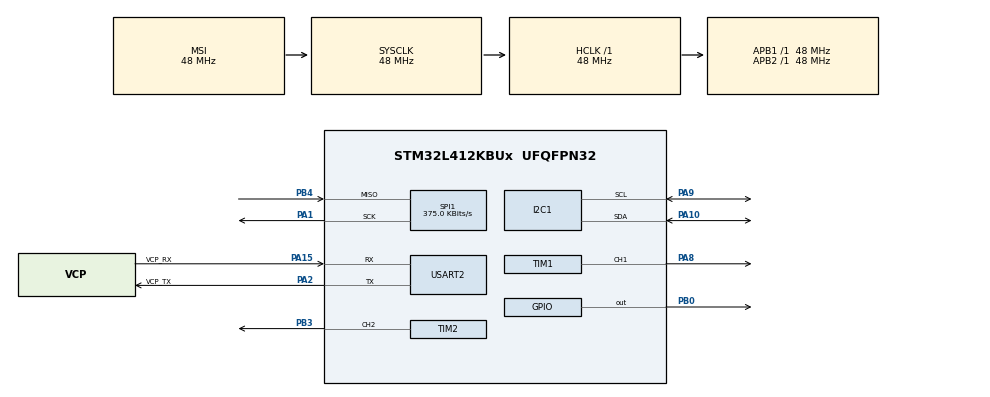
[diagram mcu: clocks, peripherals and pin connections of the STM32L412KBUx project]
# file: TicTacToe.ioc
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Dma.Request0=TIM2_CH2/CH4
Dma.Request1=TIM1_CH1
Dma.TIM1_CH1.1.Direction=DMA_MEMORY_TO_PERIPH
Dma.TIM1_CH1.1.Instance=DMA1_Channel2
Dma.TIM1_CH1.1.MemDataAlignment=DMA_MDATAALIGN_HALFWORD
Dma.TIM1_CH1.1.MemInc=DMA_MINC_ENABLE
Dma.TIM1_CH1.1.Mode=DMA_NORMAL
Dma.TIM1_CH1.1.PeriphDataAlignment=DMA_PDATAALIGN_HALFWORD
Dma.TIM1_CH1.1.PeriphInc=DMA_PINC_DISABLE
Dma.TIM1_CH1.1.Priority=DMA_PRIORITY_LOW
Dma.TIM2_CH2/CH4.0.Direction=DMA_MEMORY_TO_PERIPH
Dma.TIM2_CH2/CH4.0.Instance=DMA1_Channel7
Dma.TIM2_CH2/CH4.0.MemDataAlignment=DMA_MDATAALIGN_WORD
Dma.TIM2_CH2/CH4.0.MemInc=DMA_MINC_ENABLE
Dma.TIM2_CH2/CH4.0.Mode=DMA_CIRCULAR
Dma.TIM2_CH2/CH4.0.PeriphDataAlignment=DMA_PDATAALIGN_WORD
Dma.TIM2_CH2/CH4.0.PeriphInc=DMA_PINC_DISABLE
Dma.TIM2_CH2/CH4.0.Priority=DMA_PRIORITY_LOW
I2C1.Timing=0x10805D88
Mcu.Family=STM32L4
Mcu.Name=STM32L412KBUx
Mcu.Package=UFQFPN32
NVIC.DMA1_Channel2_IRQn=true\:0\:0\:false\:false\:true\:false\:true\:true
NVIC.DMA1_Channel7_IRQn=true\:0\:0\:false\:false\:true\:false\:true\:true
NVIC.PriorityGroup=NVIC_PRIORITYGROUP_4
NVIC.TIM2_IRQn=true\:0\:0\:false\:false\:true\:true\:true\:true
PA1.Mode=RX_Only_Simplex_Unidirect_Master
PA1.Signal=SPI1_SCK
PA10.Mode=I2C
PA10.Signal=I2C1_SDA
PA13\ (JTMS/SWDIO).GPIO_Label=SWDIO
PA13\ (JTMS/SWDIO).Mode=Serial_Wire
PA13\ (JTMS/SWDIO).Signal=SYS_JTMS-SWDIO
PA14\ (JTCK/SWCLK).GPIO_Label=SWCLK
PA14\ (JTCK/SWCLK).Mode=Serial_Wire
PA14\ (JTCK/SWCLK).Signal=SYS_JTCK-SWCLK
PA15\ (JTDI).GPIO_Label=VCP_RX
PA15\ (JTDI).Mode=Asynchronous
PA15\ (JTDI).Signal=USART2_RX
PA2.GPIO_Label=VCP_TX
PA2.Mode=Asynchronous
PA2.Signal=USART2_TX
PA8.Signal=S_TIM1_CH1
PA9.Mode=I2C
PA9.Signal=I2C1_SCL
PB0.Signal=GPIO_Output
PB3\ (JTDO/TRACESWO).Signal=S_TIM2_CH2
PB4\ (NJTRST).Mode=RX_Only_Simplex_Unidirect_Master
PB4\ (NJTRST).Signal=SPI1_MISO
PC14-OSC32_IN\ (PC14).Mode=LSE-External-Oscillator
PC14-OSC32_IN\ (PC14).Signal=RCC_OSC32_IN
PC15-OSC32_OUT\ (PC15).Mode=LSE-External-Oscillator
PC15-OSC32_OUT\ (PC15).Signal=RCC_OSC32_OUT
ProjectManager.HeapSize=0x200
ProjectManager.StackSize=0x400
ProjectManager.TargetToolchain=STM32CubeIDE
RCC.ADCFreq_Value=48000000
RCC.AHBFreq_Value=48000000
RCC.APB1Freq_Value=48000000
RCC.APB1TimFreq_Value=48000000
RCC.APB2Freq_Value=48000000
RCC.APB2TimFreq_Value=48000000
RCC.CortexFreq_Value=48000000
RCC.HCLKFreq_Value=48000000
RCC.HSE_VALUE=8000000
RCC.HSI48_VALUE=48000000
RCC.HSI_VALUE=16000000
RCC.LSE_Drive_CapabilityArg=+LSE_Drive_Capability
RCC.MSIAutoCalibration=DISABLED
RCC.MSIClockRange=RCC_MSIRANGE_11
RCC.MSI_VALUE=48000000
RCC.SYSCLKFreq_VALUE=48000000
RCC.USBFreq_Value=48000000
RCC.VCOOutputFreq_Value=384000000
SH.S_TIM1_CH1.0=TIM1_CH1,PWM Generation1 CH1
SH.S_TIM2_CH2.0=TIM2_CH2,PWM Generation2 CH2
SPI1.BaudRatePrescaler=SPI_BAUDRATEPRESCALER_128
SPI1.CLKPhase=SPI_PHASE_2EDGE
SPI1.CLKPolarity=SPI_POLARITY_HIGH
SPI1.CalculateBaudRate=375.0 KBits/s
SPI1.DataSize=SPI_DATASIZE_16BIT
SPI1.Direction=SPI_DIRECTION_2LINES_RXONLY
SPI1.FirstBit=SPI_FIRSTBIT_LSB
SPI1.Mode=SPI_MODE_MASTER
SPI1.VirtualType=VM_MASTER
TIM1.AutoReloadPreload=TIM_AUTORELOAD_PRELOAD_ENABLE
TIM1.Channel-PWM\ Generation1\ CH1=TIM_CHANNEL_1
TIM1.Period=59
TIM2.AutoReloadPreload=TIM_AUTORELOAD_PRELOAD_ENABLE
TIM2.Channel-PWM\ Generation2\ CH2=TIM_CHANNEL_2
TIM2.OCMode_PWM-PWM\ Generation2\ CH2=TIM_OCMODE_PWM2
TIM2.Period=99
TIM2.Prescaler=319
USART2.VirtualMode-Asynchronous=VM_ASYNC
VP_TIM1_VS_ClockSourceINT.Mode=Internal
VP_TIM2_VS_ClockSourceINT.Mode=Internal
board=NUCLEO-L412KB

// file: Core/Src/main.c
/* USER CODE BEGIN Header */
/**
  ******************************************************************************
  * @file           : main.c
  * @brief          : Main program body
  ******************************************************************************
  * @attention
  *
  * Copyright (c) 2026 STMicroelectronics.
  * All rights reserved.
  *
  * This software is licensed under terms that can be found in the LICENSE file
  * in the root directory of this software component.
  * If no LICENSE file comes with this software, it is provided AS-IS.
  *
  ******************************************************************************
  */
/* USER CODE END Header */
#include "main.h"
#include "dma.h"
#include "i2c.h"
#include "spi.h"
#include "tim.h"
#include "usart.h"
#include "gpio.h"

/* USER CODE BEGIN Includes */
#include "view.h"
#include "enums.h"
#include "i2c_lcd.h"
#include "retarget_stdio.h"
#include "neopixel.h"
#include "menu_controller.h"
#include "game_controller.h"
#include "keyboard.h"

/* USER CODE END Includes */

void SystemClock_Config(void);

/* USER CODE BEGIN 0 */
/*void HAL_TIM_PWM_PulseFinishedCallback(TIM_HandleTypeDef *htim)
{
    static uint32_t count=0;
    static uint8_t down_nup = 0;

    if(htim->Channel == HAL_TIM_ACTIVE_CHANNEL_2)
    {
        if (count>=500)
        {
            count=0;
            if (down_nup==0)
            {
                TIM2->CCR2++;
                if (TIM2->CCR2>99) down_nup=1;
            }
            else
            {
                TIM2->CCR2--;
                if (TIM2->CCR2<1) down_nup=0;
            }
        }
        count++;
    }
}
*/
/* USER CODE END 0 */

int main(void)
{

  /* MCU Configuration--------------------------------------------------------*/

  /* Reset of all peripherals, Initializes the Flash interface and the Systick. */
  HAL_Init();

  /* Configure the system clock */
  SystemClock_Config();

  /* Initialize all configured peripherals */
  MX_GPIO_Init();
  MX_DMA_Init();
  MX_USART2_UART_Init();
  MX_I2C1_Init();
  MX_TIM1_Init();
  MX_TIM2_Init();
  MX_SPI1_Init();
  /* USER CODE BEGIN 2 */
  RetargetInit(&huart2);
  lcd_init(&hi2c1);
 // keyboard_init(&hspi1, 10);

  /*  //test UART
  uint8_t msg[] = "Hello\r\n";
  HAL_UART_Transmit(&huart2, msg, sizeof(msg)-1, HAL_MAX_DELAY);

  //test retarget
  RetargetInit(&huart2);
  printf("System start\r\n");

*/
  /*
  //test LCD
  lcd_clr();
  char *s = "LCD OK!";
  for (int i = 0; s[i] && i < 8; i++) lcd_putc(s[i]);
  */
  /* USER CODE END 2 */

  /* Infinite loop */
  /* USER CODE BEGIN WHILE */
  //uint8_t r=0,g=0,b=0,loop=0;
  while (1)
  {
    /* USER CODE END WHILE */

    /* USER CODE BEGIN 3 */
	    game_mode_t mode;
	    uint8_t n;
	    menu_controller_run(&mode, &n);
	    game_controller_run(mode, n);
  }
  /* USER CODE END 3 */
}

void SystemClock_Config(void)
{
  RCC_OscInitTypeDef RCC_OscInitStruct = {0};
  RCC_ClkInitTypeDef RCC_ClkInitStruct = {0};

  /** Configure the main internal regulator output voltage
  */
  if (HAL_PWREx_ControlVoltageScaling(PWR_REGULATOR_VOLTAGE_SCALE1) != HAL_OK)
  {
    Error_Handler();
  }

  /** Initializes the RCC Oscillators according to the specified parameters
  * in the RCC_OscInitTypeDef structure.
  */
  RCC_OscInitStruct.OscillatorType = RCC_OSCILLATORTYPE_MSI;
  RCC_OscInitStruct.MSIState = RCC_MSI_ON;
  RCC_OscInitStruct.MSICalibrationValue = 0;
  RCC_OscInitStruct.MSIClockRange = RCC_MSIRANGE_11;
  RCC_OscInitStruct.PLL.PLLState = RCC_PLL_NONE;
  if (HAL_RCC_OscConfig(&RCC_OscInitStruct) != HAL_OK)
  {
    Error_Handler();
  }

  /** Initializes the CPU, AHB and APB buses clocks
  */
  RCC_ClkInitStruct.ClockType = RCC_CLOCKTYPE_HCLK|RCC_CLOCKTYPE_SYSCLK
                              |RCC_CLOCKTYPE_PCLK1|RCC_CLOCKTYPE_PCLK2;
  RCC_ClkInitStruct.SYSCLKSource = RCC_SYSCLKSOURCE_MSI;
  RCC_ClkInitStruct.AHBCLKDivider = RCC_SYSCLK_DIV1;
  RCC_ClkInitStruct.APB1CLKDivider = RCC_HCLK_DIV1;
  RCC_ClkInitStruct.APB2CLKDivider = RCC_HCLK_DIV1;

  if (HAL_RCC_ClockConfig(&RCC_ClkInitStruct, FLASH_LATENCY_2) != HAL_OK)
  {
    Error_Handler();
  }
}

void Error_Handler(void)
{
  __disable_irq();
  while (1)
  {
  }
}
